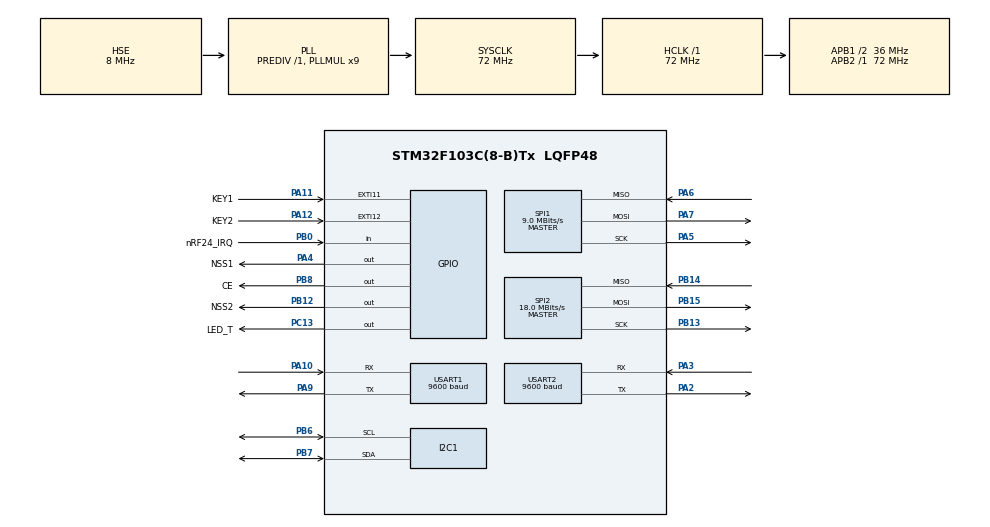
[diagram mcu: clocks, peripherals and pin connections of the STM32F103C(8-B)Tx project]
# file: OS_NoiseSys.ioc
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Dma.Request0=USART2_RX
Dma.Request1=USART2_TX
Dma.Request2=SPI1_RX
Dma.Request3=SPI1_TX
Dma.Request4=SPI2_RX
Dma.Request5=SPI2_TX
Dma.SPI1_RX.2.Direction=DMA_PERIPH_TO_MEMORY
Dma.SPI1_RX.2.Instance=DMA1_Channel2
Dma.SPI1_RX.2.MemDataAlignment=DMA_MDATAALIGN_BYTE
Dma.SPI1_RX.2.MemInc=DMA_MINC_ENABLE
Dma.SPI1_RX.2.Mode=DMA_NORMAL
Dma.SPI1_RX.2.PeriphDataAlignment=DMA_PDATAALIGN_BYTE
Dma.SPI1_RX.2.PeriphInc=DMA_PINC_DISABLE
Dma.SPI1_RX.2.Priority=DMA_PRIORITY_LOW
Dma.SPI1_TX.3.Direction=DMA_MEMORY_TO_PERIPH
Dma.SPI1_TX.3.Instance=DMA1_Channel3
Dma.SPI1_TX.3.MemDataAlignment=DMA_MDATAALIGN_BYTE
Dma.SPI1_TX.3.MemInc=DMA_MINC_ENABLE
Dma.SPI1_TX.3.Mode=DMA_NORMAL
Dma.SPI1_TX.3.PeriphDataAlignment=DMA_PDATAALIGN_BYTE
Dma.SPI1_TX.3.PeriphInc=DMA_PINC_DISABLE
Dma.SPI1_TX.3.Priority=DMA_PRIORITY_LOW
Dma.SPI2_RX.4.Direction=DMA_PERIPH_TO_MEMORY
Dma.SPI2_RX.4.Instance=DMA1_Channel4
Dma.SPI2_RX.4.MemDataAlignment=DMA_MDATAALIGN_BYTE
Dma.SPI2_RX.4.MemInc=DMA_MINC_ENABLE
Dma.SPI2_RX.4.Mode=DMA_CIRCULAR
Dma.SPI2_RX.4.PeriphDataAlignment=DMA_PDATAALIGN_BYTE
Dma.SPI2_RX.4.PeriphInc=DMA_PINC_DISABLE
Dma.SPI2_RX.4.Priority=DMA_PRIORITY_LOW
Dma.SPI2_TX.5.Direction=DMA_MEMORY_TO_PERIPH
Dma.SPI2_TX.5.Instance=DMA1_Channel5
Dma.SPI2_TX.5.MemDataAlignment=DMA_MDATAALIGN_BYTE
Dma.SPI2_TX.5.MemInc=DMA_MINC_ENABLE
Dma.SPI2_TX.5.Mode=DMA_NORMAL
Dma.SPI2_TX.5.PeriphDataAlignment=DMA_PDATAALIGN_BYTE
Dma.SPI2_TX.5.PeriphInc=DMA_PINC_DISABLE
Dma.SPI2_TX.5.Priority=DMA_PRIORITY_LOW
Dma.USART2_RX.0.Direction=DMA_PERIPH_TO_MEMORY
Dma.USART2_RX.0.Instance=DMA1_Channel6
Dma.USART2_RX.0.MemDataAlignment=DMA_MDATAALIGN_BYTE
Dma.USART2_RX.0.MemInc=DMA_MINC_ENABLE
Dma.USART2_RX.0.Mode=DMA_NORMAL
Dma.USART2_RX.0.PeriphDataAlignment=DMA_PDATAALIGN_BYTE
Dma.USART2_RX.0.PeriphInc=DMA_PINC_DISABLE
Dma.USART2_RX.0.Priority=DMA_PRIORITY_LOW
Dma.USART2_TX.1.Direction=DMA_MEMORY_TO_PERIPH
Dma.USART2_TX.1.Instance=DMA1_Channel7
Dma.USART2_TX.1.MemDataAlignment=DMA_MDATAALIGN_BYTE
Dma.USART2_TX.1.MemInc=DMA_MINC_ENABLE
Dma.USART2_TX.1.Mode=DMA_NORMAL
Dma.USART2_TX.1.PeriphDataAlignment=DMA_PDATAALIGN_BYTE
Dma.USART2_TX.1.PeriphInc=DMA_PINC_DISABLE
Dma.USART2_TX.1.Priority=DMA_PRIORITY_LOW
FREERTOS.Tasks01=LED_Task,24,128,StartDefaultTask,Default,NULL,Static,LED_TaskBuffer,LED_TaskControlBlock
FREERTOS.configTOTAL_HEAP_SIZE=10240
Mcu.Family=STM32F1
Mcu.Name=STM32F103C(8-B)Tx
Mcu.Package=LQFP48
NVIC.DMA1_Channel2_IRQn=true\:5\:0\:false\:false\:true\:true\:false\:true\:true
NVIC.DMA1_Channel3_IRQn=true\:5\:0\:false\:false\:true\:true\:false\:true\:true
NVIC.DMA1_Channel4_IRQn=true\:5\:0\:false\:false\:true\:true\:false\:true\:true
NVIC.DMA1_Channel5_IRQn=true\:5\:0\:false\:false\:true\:true\:false\:true\:true
NVIC.DMA1_Channel6_IRQn=true\:5\:0\:false\:false\:true\:true\:false\:true\:true
NVIC.DMA1_Channel7_IRQn=true\:5\:0\:false\:false\:true\:true\:false\:true\:true
NVIC.PriorityGroup=NVIC_PRIORITYGROUP_4
NVIC.TIM4_IRQn=true\:15\:0\:false\:false\:true\:false\:false\:true\:true
NVIC.TimeBase=TIM4_IRQn
NVIC.TimeBaseIP=TIM4
NVIC.USART1_IRQn=true\:5\:0\:false\:false\:true\:true\:true\:true\:true
NVIC.USART2_IRQn=true\:5\:0\:false\:false\:true\:true\:true\:true\:true
PA10.Mode=Asynchronous
PA10.Signal=USART1_RX
PA11.GPIO_Label=KEY1
PA11.Signal=GPXTI11
PA12.GPIO_Label=KEY2
PA12.Signal=GPXTI12
PA13.Mode=Serial_Wire
PA13.Signal=SYS_JTMS-SWDIO
PA14.Mode=Serial_Wire
PA14.Signal=SYS_JTCK-SWCLK
PA2.Mode=Asynchronous
PA2.Signal=USART2_TX
PA3.Mode=Asynchronous
PA3.Signal=USART2_RX
PA4.GPIO_Label=NSS1
PA4.Signal=GPIO_Output
PA5.Mode=Full_Duplex_Master
PA5.Signal=SPI1_SCK
PA6.Mode=Full_Duplex_Master
PA6.Signal=SPI1_MISO
PA7.Mode=Full_Duplex_Master
PA7.Signal=SPI1_MOSI
PA9.Mode=Asynchronous
PA9.Signal=USART1_TX
PB0.GPIO_Label=nRF24_IRQ
PB0.GPIO_PuPd=GPIO_PULLUP
PB0.Signal=GPIO_Input
PB12.GPIO_Label=NSS2
PB12.Signal=GPIO_Output
PB13.Mode=Full_Duplex_Master
PB13.Signal=SPI2_SCK
PB14.Mode=Full_Duplex_Master
PB14.Signal=SPI2_MISO
PB15.Mode=Full_Duplex_Master
PB15.Signal=SPI2_MOSI
PB6.Mode=I2C
PB6.Signal=I2C1_SCL
PB7.Mode=I2C
PB7.Signal=I2C1_SDA
PB8.GPIO_Label=CE
PB8.Signal=GPIO_Output
PC13-TAMPER-RTC.GPIO_Label=LED_T
PC13-TAMPER-RTC.Signal=GPIO_Output
PC14-OSC32_IN.Mode=LSE-External-Oscillator
PC14-OSC32_IN.Signal=RCC_OSC32_IN
PC15-OSC32_OUT.Mode=LSE-External-Oscillator
PC15-OSC32_OUT.Signal=RCC_OSC32_OUT
PD0-OSC_IN.Mode=HSE-External-Oscillator
PD0-OSC_IN.Signal=RCC_OSC_IN
PD1-OSC_OUT.Mode=HSE-External-Oscillator
PD1-OSC_OUT.Signal=RCC_OSC_OUT
ProjectManager.HeapSize=0x200
ProjectManager.StackSize=0x400
ProjectManager.TargetToolchain=MDK-ARM V5.32
RCC.AHBFreq_Value=72000000
RCC.APB1CLKDivider=RCC_HCLK_DIV2
RCC.APB1Freq_Value=36000000
RCC.APB1TimFreq_Value=72000000
RCC.APB2Freq_Value=72000000
RCC.APB2TimFreq_Value=72000000
RCC.HCLKFreq_Value=72000000
RCC.PLLMUL=RCC_PLL_MUL9
RCC.PLLSourceVirtual=RCC_PLLSOURCE_HSE
RCC.SYSCLKFreq_VALUE=72000000
RCC.SYSCLKSource=RCC_SYSCLKSOURCE_PLLCLK
RCC.USBFreq_Value=72000000
SPI1.BaudRatePrescaler=SPI_BAUDRATEPRESCALER_8
SPI1.CalculateBaudRate=9.0 MBits/s
SPI1.Direction=SPI_DIRECTION_2LINES
SPI1.Mode=SPI_MODE_MASTER
SPI1.VirtualType=VM_MASTER
SPI2.CalculateBaudRate=18.0 MBits/s
SPI2.Direction=SPI_DIRECTION_2LINES
SPI2.Mode=SPI_MODE_MASTER
SPI2.VirtualType=VM_MASTER
USART1.BaudRate=9600
USART1.VirtualMode=VM_ASYNC
USART2.BaudRate=9600
USART2.VirtualMode=VM_ASYNC
VP_FREERTOS_VS_CMSIS_V2.Mode=CMSIS_V2
VP_SYS_VS_tim4.Mode=TIM4
board=custom

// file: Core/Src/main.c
/* USER CODE BEGIN Header */
/**
 ******************************************************************************
 * @file           : main.c
 * @brief          : Main program body
 ******************************************************************************
 * @attention
 *
 * Copyright (c) 2023 STMicroelectronics.
 * All rights reserved.
 *
 * This software is licensed under terms that can be found in the LICENSE file
 * in the root directory of this software component.
 * If no LICENSE file comes with this software, it is provided AS-IS.
 *
 ******************************************************************************
 */
/* USER CODE END Header */
#include "main.h"
#include "cmsis_os.h"
#include "dma.h"
#include "i2c.h"
#include "spi.h"
#include "usart.h"
#include "gpio.h"

/* USER CODE BEGIN Includes */

/* standard library */
#include "stdio.h"
#include "string.h"
#include "stdlib.h"
/* hardware driver */
#include "usart.h"
#include "OLED.h"
#include "24l01.h"
#include "W25Q128.h"
#include "noisen.h"
#include "user_TasksInit.h"

/* USER CODE END Includes */

/* USER CODE BEGIN PV */
uint32_t FreeRTOSRunTimeTicks; // FreeRTOS Run Time ticks counter
/* USER CODE END PV */

void SystemClock_Config(void);
void MX_FREERTOS_Init(void);

int main(void)
{

    /* MCU Configuration--------------------------------------------------------*/

    /* Reset of all peripherals, Initializes the Flash interface and the Systick. */
    HAL_Init();

    /* Configure the system clock */
    SystemClock_Config();

    /* Initialize all configured peripherals */
    MX_GPIO_Init();
    MX_DMA_Init();
    MX_USART1_UART_Init();
    MX_USART2_UART_Init();
    MX_I2C1_Init();
    MX_SPI1_Init();
    MX_SPI2_Init();

    /* Init scheduler */
    osKernelInitialize(); /* Call init function for freertos objects (in freertos.c) */
    MX_FREERTOS_Init();
    User_Tasks_Init();
    /* Start scheduler */
    osKernelStart();

    /* We should never get here as control is now taken by the scheduler */
    /* Infinite loop */
    while (1)
    {

    }
}

void SystemClock_Config(void)
{
    RCC_OscInitTypeDef RCC_OscInitStruct = {0};
    RCC_ClkInitTypeDef RCC_ClkInitStruct = {0};

    /** Initializes the RCC Oscillators according to the specified parameters
     * in the RCC_OscInitTypeDef structure.
     */
    RCC_OscInitStruct.OscillatorType = RCC_OSCILLATORTYPE_HSE;
    RCC_OscInitStruct.HSEState = RCC_HSE_ON;
    RCC_OscInitStruct.HSEPredivValue = RCC_HSE_PREDIV_DIV1;
    RCC_OscInitStruct.HSIState = RCC_HSI_ON;
    RCC_OscInitStruct.PLL.PLLState = RCC_PLL_ON;
    RCC_OscInitStruct.PLL.PLLSource = RCC_PLLSOURCE_HSE;
    RCC_OscInitStruct.PLL.PLLMUL = RCC_PLL_MUL9;
    if (HAL_RCC_OscConfig(&RCC_OscInitStruct) != HAL_OK)
    {
        Error_Handler();
    }

    /** Initializes the CPU, AHB and APB buses clocks
     */
    RCC_ClkInitStruct.ClockType = RCC_CLOCKTYPE_HCLK | RCC_CLOCKTYPE_SYSCLK | RCC_CLOCKTYPE_PCLK1 | RCC_CLOCKTYPE_PCLK2;
    RCC_ClkInitStruct.SYSCLKSource = RCC_SYSCLKSOURCE_PLLCLK;
    RCC_ClkInitStruct.AHBCLKDivider = RCC_SYSCLK_DIV1;
    RCC_ClkInitStruct.APB1CLKDivider = RCC_HCLK_DIV2;
    RCC_ClkInitStruct.APB2CLKDivider = RCC_HCLK_DIV1;

    if (HAL_RCC_ClockConfig(&RCC_ClkInitStruct, FLASH_LATENCY_2) != HAL_OK)
    {
        Error_Handler();
    }
}

void HAL_TIM_PeriodElapsedCallback(TIM_HandleTypeDef *htim)
{
    if (htim->Instance == TIM4)
    {
        HAL_IncTick();
    }
}

void Error_Handler(void)
{
    __disable_irq();
    while (1)
    {
    }
}

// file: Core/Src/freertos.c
/* USER CODE BEGIN Header */
/**
 ******************************************************************************
 * File Name          : freertos.c
 * Description        : Code for freertos applications
 ******************************************************************************
 * @attention
 *
 * Copyright (c) 2023 STMicroelectronics.
 * All rights reserved.
 *
 * This software is licensed under terms that can be found in the LICENSE file
 * in the root directory of this software component.
 * If no LICENSE file comes with this software, it is provided AS-IS.
 *
 ******************************************************************************
 */
/* USER CODE END Header */

#include "FreeRTOS.h"
#include "task.h"
#include "main.h"
#include "cmsis_os.h"

typedef StaticTask_t osStaticThreadDef_t;

/* Definitions for LED_Task */
osThreadId_t LED_TaskHandle;
uint32_t LED_TaskBuffer[ 128 ];
osStaticThreadDef_t LED_TaskControlBlock;
const osThreadAttr_t LED_Task_attributes = {
  .name = "LED_Task",
  .cb_mem = &LED_TaskControlBlock,
  .cb_size = sizeof(LED_TaskControlBlock),
  .stack_mem = &LED_TaskBuffer[0],
  .stack_size = sizeof(LED_TaskBuffer),
  .priority = (osPriority_t) osPriorityNormal,
};

/* USER CODE BEGIN FunctionPrototypes */
void ConfigureTimerForRunTimeStats(void)
{
    FreeRTOSRunTimeTicks = 0;
}
/* USER CODE END FunctionPrototypes */

void StartDefaultTask(void *argument);

void MX_FREERTOS_Init(void); /* (MISRA C 2004 rule 8.1) */

void MX_FREERTOS_Init(void) {

  /* Create the thread(s) */
  /* creation of LED_Task */
  LED_TaskHandle = osThreadNew(StartDefaultTask, NULL, &LED_Task_attributes);

}

void StartDefaultTask(void *argument)
{
  /* USER CODE BEGIN StartDefaultTask */
    /* Infinite loop */
    for (;;)
    {
        osDelay(0xffffffff);
    }
  /* USER CODE END StartDefaultTask */
}
